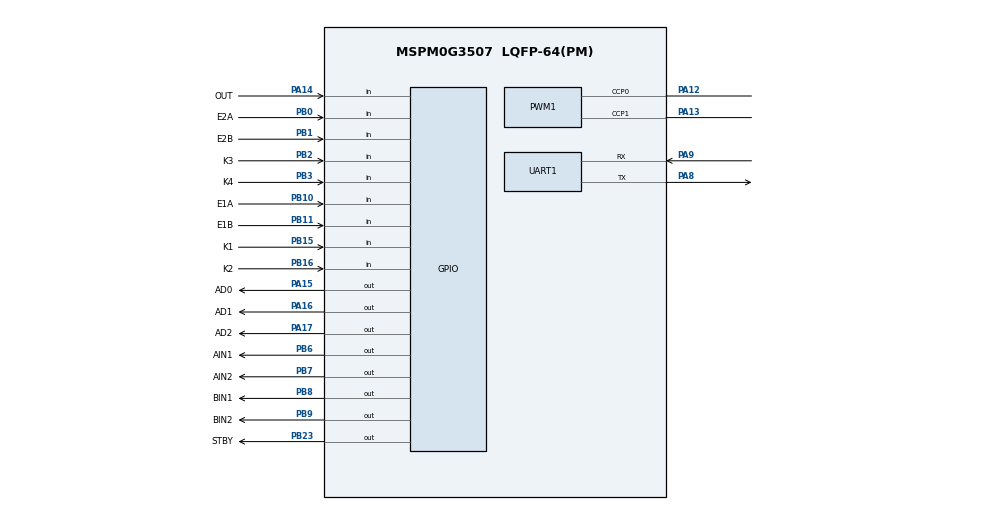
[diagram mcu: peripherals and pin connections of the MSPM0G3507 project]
//@cliArgs --device "MSPM0G350X" --package "LQFP-64(PM)" --part "Default"
//@v2CliArgs --device "MSPM0G3507" --package "LQFP-64(PM)"
// @cliArgs --board /ti/boards/LP_MSPM0G3507 --rtos nortos

const GPIO   = scripting.addModule("/ti/driverlib/GPIO", {}, false);
const GPIO1  = GPIO.addInstance();
const GPIO2  = GPIO.addInstance();
const GPIO3  = GPIO.addInstance();
const GPIO4  = GPIO.addInstance();
const PWM    = scripting.addModule("/ti/driverlib/PWM", {}, false);
const PWM1   = PWM.addInstance();
const TIMER  = scripting.addModule("/ti/driverlib/TIMER", {}, false);
const TIMER1 = TIMER.addInstance();
const UART   = scripting.addModule("/ti/driverlib/UART", {}, false);
const UART1  = UART.addInstance();
const SYSCTL = scripting.addModule("/ti/driverlib/SYSCTL");

const Board = scripting.addModule("/ti/driverlib/Board", {}, false);

GPIO1.$name = "GPIO_MOTOR";
GPIO1.associatedPins.create(5);
GPIO1.associatedPins[0].$name        = "AIN1";
GPIO1.associatedPins[0].assignedPort = "PORTB";
GPIO1.associatedPins[0].assignedPin  = "6";
GPIO1.associatedPins[0].pin.$assign  = "PB6";
GPIO1.associatedPins[0].initialValue = "CLEARED";
GPIO1.associatedPins[1].$name        = "AIN2";
GPIO1.associatedPins[1].assignedPort = "PORTB";
GPIO1.associatedPins[1].assignedPin  = "7";
GPIO1.associatedPins[1].pin.$assign  = "PB7";
GPIO1.associatedPins[1].initialValue = "CLEARED";
GPIO1.associatedPins[2].$name        = "BIN1";
GPIO1.associatedPins[2].assignedPort = "PORTB";
GPIO1.associatedPins[2].assignedPin  = "8";
GPIO1.associatedPins[2].pin.$assign  = "PB8";
GPIO1.associatedPins[2].initialValue = "CLEARED";
GPIO1.associatedPins[3].$name        = "BIN2";
GPIO1.associatedPins[3].assignedPort = "PORTB";
GPIO1.associatedPins[3].assignedPin  = "9";
GPIO1.associatedPins[3].pin.$assign  = "PB9";
GPIO1.associatedPins[3].initialValue = "CLEARED";
GPIO1.associatedPins[4].$name        = "STBY";
GPIO1.associatedPins[4].assignedPort = "PORTB";
GPIO1.associatedPins[4].assignedPin  = "23";
GPIO1.associatedPins[4].pin.$assign  = "PB23";
GPIO1.associatedPins[4].initialValue = "CLEARED";

GPIO2.$name = "GPIO_ENCODER";
GPIO2.associatedPins.create(4);
GPIO2.associatedPins[0].$name            = "E1A";
GPIO2.associatedPins[0].assignedPort     = "PORTB";
GPIO2.associatedPins[0].assignedPin      = "10";
GPIO2.associatedPins[0].pin.$assign      = "PB10";
GPIO2.associatedPins[0].direction        = "INPUT";
GPIO2.associatedPins[0].internalResistor = "PULL_UP";
GPIO2.associatedPins[0].interruptEn      = true;
GPIO2.associatedPins[0].polarity         = "RISE_FALL";
GPIO2.associatedPins[1].$name            = "E1B";
GPIO2.associatedPins[1].assignedPort     = "PORTB";
GPIO2.associatedPins[1].assignedPin      = "11";
GPIO2.associatedPins[1].pin.$assign      = "PB11";
GPIO2.associatedPins[1].direction        = "INPUT";
GPIO2.associatedPins[1].internalResistor = "PULL_UP";
GPIO2.associatedPins[2].$name            = "E2A";
GPIO2.associatedPins[2].assignedPort     = "PORTB";
GPIO2.associatedPins[2].assignedPin      = "0";
GPIO2.associatedPins[2].pin.$assign      = "PB0";
GPIO2.associatedPins[2].direction        = "INPUT";
GPIO2.associatedPins[2].internalResistor = "PULL_UP";
GPIO2.associatedPins[2].interruptEn      = true;
GPIO2.associatedPins[2].polarity         = "RISE_FALL";
GPIO2.associatedPins[3].$name            = "E2B";
GPIO2.associatedPins[3].assignedPort     = "PORTB";
GPIO2.associatedPins[3].assignedPin      = "1";
GPIO2.associatedPins[3].pin.$assign      = "PB1";
GPIO2.associatedPins[3].direction        = "INPUT";
GPIO2.associatedPins[3].internalResistor = "PULL_UP";

GPIO3.$name = "GPIO_GRAYSCALE";
GPIO3.associatedPins.create(4);
GPIO3.associatedPins[0].$name            = "OUT";
GPIO3.associatedPins[0].assignedPort     = "PORTA";
GPIO3.associatedPins[0].assignedPin      = "14";
GPIO3.associatedPins[0].pin.$assign      = "PA14";
GPIO3.associatedPins[0].direction        = "INPUT";
GPIO3.associatedPins[0].internalResistor = "PULL_UP";
GPIO3.associatedPins[1].$name            = "AD0";
GPIO3.associatedPins[1].assignedPort     = "PORTA";
GPIO3.associatedPins[1].assignedPin      = "15";
GPIO3.associatedPins[1].pin.$assign      = "PA15";
GPIO3.associatedPins[1].initialValue     = "CLEARED";
GPIO3.associatedPins[2].$name            = "AD1";
GPIO3.associatedPins[2].assignedPort     = "PORTA";
GPIO3.associatedPins[2].assignedPin      = "16";
GPIO3.associatedPins[2].pin.$assign      = "PA16";
GPIO3.associatedPins[2].initialValue     = "CLEARED";
GPIO3.associatedPins[3].$name            = "AD2";
GPIO3.associatedPins[3].assignedPort     = "PORTA";
GPIO3.associatedPins[3].assignedPin      = "17";
GPIO3.associatedPins[3].pin.$assign      = "PA17";
GPIO3.associatedPins[3].initialValue     = "CLEARED";

GPIO4.$name = "GPIO_KEYS";
GPIO4.associatedPins.create(4);
GPIO4.associatedPins[0].$name            = "K1";
GPIO4.associatedPins[0].assignedPort     = "PORTB";
GPIO4.associatedPins[0].assignedPin      = "15";
GPIO4.associatedPins[0].pin.$assign      = "PB15";
GPIO4.associatedPins[0].direction        = "INPUT";
GPIO4.associatedPins[0].internalResistor = "PULL_UP";
GPIO4.associatedPins[1].$name            = "K2";
GPIO4.associatedPins[1].assignedPort     = "PORTB";
GPIO4.associatedPins[1].assignedPin      = "16";
GPIO4.associatedPins[1].pin.$assign      = "PB16";
GPIO4.associatedPins[1].direction        = "INPUT";
GPIO4.associatedPins[1].internalResistor = "PULL_UP";
GPIO4.associatedPins[2].$name            = "K3";
GPIO4.associatedPins[2].assignedPort     = "PORTB";
GPIO4.associatedPins[2].assignedPin      = "2";
GPIO4.associatedPins[2].pin.$assign      = "PB2";
GPIO4.associatedPins[2].direction        = "INPUT";
GPIO4.associatedPins[2].internalResistor = "PULL_UP";
GPIO4.associatedPins[3].$name            = "K4";
GPIO4.associatedPins[3].assignedPort     = "PORTB";
GPIO4.associatedPins[3].assignedPin      = "3";
GPIO4.associatedPins[3].pin.$assign      = "PB3";
GPIO4.associatedPins[3].direction        = "INPUT";
GPIO4.associatedPins[3].internalResistor = "PULL_UP";

PWM1.$name                      = "PWM_MOTOR";
PWM1.timerCount                 = 1600;
PWM1.peripheral.$assign         = "TIMG0";
PWM1.peripheral.ccp0Pin.$assign = "PA12";
PWM1.peripheral.ccp1Pin.$assign = "PA13";
PWM1.PWM_CHANNEL_0.$name        = "LEFT_PWM";
PWM1.PWM_CHANNEL_0.dutyCycle    = 0;
PWM1.PWM_CHANNEL_1.$name        = "RIGHT_PWM";
PWM1.PWM_CHANNEL_1.dutyCycle    = 0;

TIMER1.$name              = "TIMER_SYS";
TIMER1.profile            = "Basic_Periodic";
TIMER1.timerPeriod        = "1 ms";
TIMER1.peripheral.$assign = "TIMG8";

UART1.$name                  = "UART_MAIN";
UART1.profile                = "CONFIG_PROFILE_1";
UART1.peripheral.$assign     = "UART1";
UART1.targetBaudRate         = 9600;
UART1.enableInternalLoopback = false;
UART1.enableFIFO            = false;
UART1.enabledInterrupts      = ["RX"];
UART1.peripheral.txPin.$assign = "PA8";
UART1.peripheral.rxPin.$assign = "PA9";

SYSCTL.forceDefaultClkConfig = true;
SYSCTL.clockTreeEn = true;
